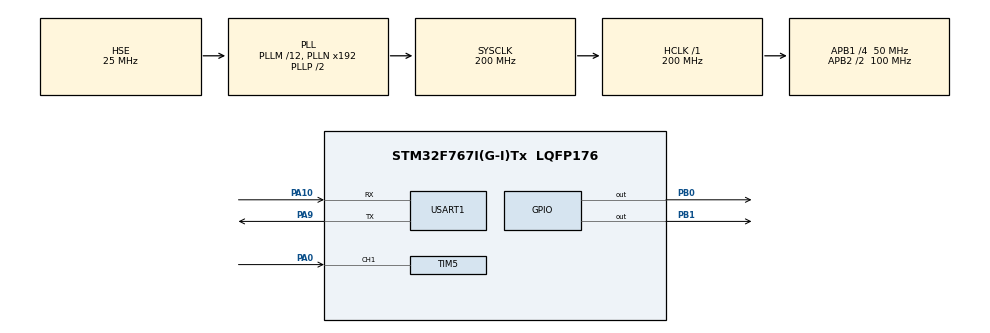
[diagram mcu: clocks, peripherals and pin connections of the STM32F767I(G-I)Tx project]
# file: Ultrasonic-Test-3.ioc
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Mcu.Family=STM32F7
Mcu.Name=STM32F767I(G-I)Tx
Mcu.Package=LQFP176
NVIC.PriorityGroup=NVIC_PRIORITYGROUP_4
NVIC.TIM5_IRQn=true\:0\:0\:false\:false\:true\:true\:true
NVIC.TIM6_DAC_IRQn=true\:0\:0\:false\:false\:true\:true\:true
PA0/WKUP.Signal=S_TIM5_CH1
PA10.Mode=Asynchronous
PA10.Signal=USART1_RX
PA13.Mode=Serial_Wire
PA13.Signal=SYS_JTMS-SWDIO
PA14.Mode=Serial_Wire
PA14.Signal=SYS_JTCK-SWCLK
PA9.Mode=Asynchronous
PA9.Signal=USART1_TX
PB0.Signal=GPIO_Output
PB1.Signal=GPIO_Output
PH0/OSC_IN.Mode=HSE-External-Oscillator
PH0/OSC_IN.Signal=RCC_OSC_IN
PH1/OSC_OUT.Mode=HSE-External-Oscillator
PH1/OSC_OUT.Signal=RCC_OSC_OUT
ProjectManager.HeapSize=0x200
ProjectManager.StackSize=0x400
ProjectManager.TargetToolchain=MDK-ARM V5
RCC.AHBFreq_Value=200000000
RCC.APB1CLKDivider=RCC_HCLK_DIV4
RCC.APB1Freq_Value=50000000
RCC.APB1TimFreq_Value=100000000
RCC.APB2CLKDivider=RCC_HCLK_DIV2
RCC.APB2Freq_Value=100000000
RCC.APB2TimFreq_Value=200000000
RCC.CortexFreq_Value=200000000
RCC.HCLKFreq_Value=200000000
RCC.HSE_VALUE=25000000
RCC.HSI_VALUE=16000000
RCC.LSE_VALUE=32768
RCC.PLLM=12
RCC.PLLSourceVirtual=RCC_PLLSOURCE_HSE
RCC.SYSCLKFreq_VALUE=200000000
RCC.SYSCLKSource=RCC_SYSCLKSOURCE_PLLCLK
RCC.USBFreq_Value=200000000
RCC.VCOOutputFreq_Value=400000000
SH.S_TIM5_CH1.0=TIM5_CH1,Input_Capture1_from_TI1
TIM5.Channel-Input_Capture1_from_TI1=TIM_CHANNEL_1
TIM5.Period=0xffffffff
TIM5.Prescaler=99
TIM6.Prescaler=99
TIM6.TIM_MasterOutputTrigger=TIM_TRGO_ENABLE
USART1.DMADisableonRxErrorParam=ADVFEATURE_DMA_DISABLEONRXERROR
USART1.OverrunDisableParam=ADVFEATURE_OVERRUN_DISABLE
USART1.VirtualMode-Asynchronous=VM_ASYNC
VP_TIM5_VS_ClockSourceINT.Mode=Internal
VP_TIM6_VS_ClockSourceINT.Mode=Enable_Timer
board=custom

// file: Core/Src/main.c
/* USER CODE BEGIN Header */
/**
  ******************************************************************************
  * @file           : main.c
  * @brief          : Main program body
  ******************************************************************************
  * @attention
  *
  * <h2><center>&copy; Copyright (c) 2021 STMicroelectronics.
  * All rights reserved.</center></h2>
  *
  * This software component is licensed by ST under BSD 3-Clause license,
  * the "License"; You may not use this file except in compliance with the
  * License. You may obtain a copy of the License at:
  *                        opensource.org/licenses/BSD-3-Clause
  *
  ******************************************************************************
  */
/* USER CODE END Header */
#include "main.h"
#include "tim.h"
#include "usart.h"
#include "gpio.h"

/* USER CODE BEGIN Includes */

#include "stdio.h"

/* USER CODE END Includes */

void SystemClock_Config(void);

/* USER CODE BEGIN 0 */
extern uint16_t Ultrasonic_us;
/* USER CODE END 0 */

int main(void)
{

  /* MCU Configuration--------------------------------------------------------*/

  /* Reset of all peripherals, Initializes the Flash interface and the Systick. */
  HAL_Init();

  /* Configure the system clock */
  SystemClock_Config();

  /* Initialize all configured peripherals */
  MX_GPIO_Init();
  MX_TIM5_Init();
  MX_TIM6_Init();
  MX_USART1_UART_Init();

  /* Infinite loop */
  while (1)
  {
//		printf("While loop Running!\r\n");
		HAL_GPIO_TogglePin(GPIOB,GPIO_PIN_0);

		Sonic_Trig(20);
		if(Ultrasonic_us != 0)
			printf("Ultrasonic distance: %d cm \r\n",(int)(Ultrasonic_us * 17.0 / 1000));
		HAL_Delay(200);

  }
}

void SystemClock_Config(void)
{
  RCC_OscInitTypeDef RCC_OscInitStruct = {0};
  RCC_ClkInitTypeDef RCC_ClkInitStruct = {0};
  RCC_PeriphCLKInitTypeDef PeriphClkInitStruct = {0};

  /** Configure the main internal regulator output voltage
  */
  __HAL_RCC_PWR_CLK_ENABLE();
  __HAL_PWR_VOLTAGESCALING_CONFIG(PWR_REGULATOR_VOLTAGE_SCALE1);
  /** Initializes the RCC Oscillators according to the specified parameters
  * in the RCC_OscInitTypeDef structure.
  */
  RCC_OscInitStruct.OscillatorType = RCC_OSCILLATORTYPE_HSE;
  RCC_OscInitStruct.HSEState = RCC_HSE_ON;
  RCC_OscInitStruct.PLL.PLLState = RCC_PLL_ON;
  RCC_OscInitStruct.PLL.PLLSource = RCC_PLLSOURCE_HSE;
  RCC_OscInitStruct.PLL.PLLM = 12;
  RCC_OscInitStruct.PLL.PLLN = 192;
  RCC_OscInitStruct.PLL.PLLP = RCC_PLLP_DIV2;
  RCC_OscInitStruct.PLL.PLLQ = 2;
  if (HAL_RCC_OscConfig(&RCC_OscInitStruct) != HAL_OK)
  {
    Error_Handler();
  }
  /** Activate the Over-Drive mode
  */
  if (HAL_PWREx_EnableOverDrive() != HAL_OK)
  {
    Error_Handler();
  }
  /** Initializes the CPU, AHB and APB buses clocks
  */
  RCC_ClkInitStruct.ClockType = RCC_CLOCKTYPE_HCLK|RCC_CLOCKTYPE_SYSCLK
                              |RCC_CLOCKTYPE_PCLK1|RCC_CLOCKTYPE_PCLK2;
  RCC_ClkInitStruct.SYSCLKSource = RCC_SYSCLKSOURCE_PLLCLK;
  RCC_ClkInitStruct.AHBCLKDivider = RCC_SYSCLK_DIV1;
  RCC_ClkInitStruct.APB1CLKDivider = RCC_HCLK_DIV4;
  RCC_ClkInitStruct.APB2CLKDivider = RCC_HCLK_DIV2;

  if (HAL_RCC_ClockConfig(&RCC_ClkInitStruct, FLASH_LATENCY_6) != HAL_OK)
  {
    Error_Handler();
  }
  PeriphClkInitStruct.PeriphClockSelection = RCC_PERIPHCLK_USART1;
  PeriphClkInitStruct.Usart1ClockSelection = RCC_USART1CLKSOURCE_PCLK2;
  if (HAL_RCCEx_PeriphCLKConfig(&PeriphClkInitStruct) != HAL_OK)
  {
    Error_Handler();
  }
}

void Error_Handler(void)
{
}

/************************ (C) COPYRIGHT STMicroelectronics *****END OF FILE****/
